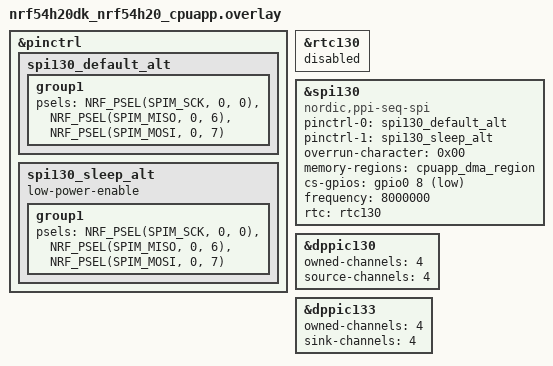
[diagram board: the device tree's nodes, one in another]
/*
 * Copyright (c) 2026 Nordic Semiconductor ASA
 *
 * SPDX-License-Identifier: LicenseRef-Nordic-5-Clause
 */

&pinctrl {
	spi130_default_alt: spi130_default_alt {
		group1 {
			psels = <NRF_PSEL(SPIM_SCK, 0, 0)>,
				<NRF_PSEL(SPIM_MISO, 0, 6)>,
				<NRF_PSEL(SPIM_MOSI, 0, 7)>;
		};
	};

	spi130_sleep_alt: spi130_sleep_alt {
		group1 {
			psels = <NRF_PSEL(SPIM_SCK, 0, 0)>,
				<NRF_PSEL(SPIM_MISO, 0, 6)>,
				<NRF_PSEL(SPIM_MOSI, 0, 7)>;
		};

		low-power-enable;
	};
};

&rtc130 {
	status = "reserved";
};

sample_spi: &spi130 {
	compatible = "nordic,ppi-seq-spi";
	status = "okay";
	pinctrl-0 = <&spi130_default_alt>;
	pinctrl-1 = <&spi130_sleep_alt>;
	pinctrl-names = "default", "sleep";
	overrun-character = <0x00>;
	memory-regions = <&cpuapp_dma_region>;
	cs-gpios = <&gpio0 8 GPIO_ACTIVE_LOW>;
	frequency = <8000000>;
	rtc = <&rtc130>;
};

&dppic130 {
	status = "okay";
	owned-channels = <4>;
	/* RTC130->SPI130 */
	source-channels = <4>;
};

&dppic133 {
	status = "okay";
	owned-channels = <4>;
	/* SPI130<-RTC130/GRTC */
	sink-channels = <4>;
};
